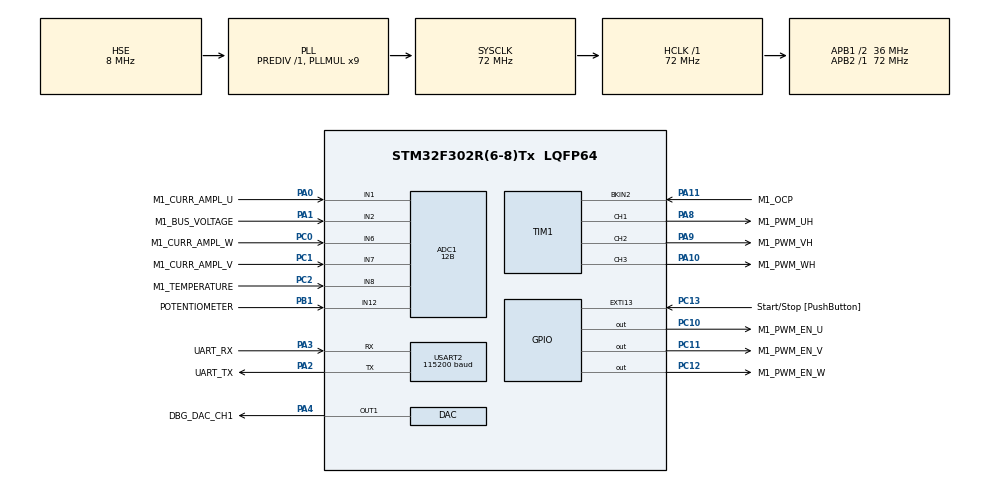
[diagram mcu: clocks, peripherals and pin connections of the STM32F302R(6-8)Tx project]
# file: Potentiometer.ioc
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ADC1.Channel-1\#ChannelRegularConversion=ADC_CHANNEL_2
ADC1.Channel-2\#ChannelRegularConversion=ADC_CHANNEL_8
ADC1.Channel-4\#ChannelRegularConversion=ADC_CHANNEL_12
ADC1.ClockPrescaler=ADC_CLOCK_SYNC_PCLK_DIV1
ADC1.ContinuousConvMode=DISABLE
ADC1.DMAContinuousRequests=DISABLE
ADC1.DataAlign=ADC_DATAALIGN_LEFT
ADC1.DiscontinuousConvMode=DISABLE
ADC1.EOCSelection=ADC_EOC_SINGLE_CONV
ADC1.EnableAnalogWatchDog1=false
ADC1.EnableAnalogWatchDog2=false
ADC1.EnableAnalogWatchDog3=false
ADC1.EnableInjectedConversion=ENABLE
ADC1.EnableRegularConversion=ENABLE
ADC1.ExternalTrigConv=ADC_SOFTWARE_START
ADC1.ExternalTrigConvEdge=ADC_EXTERNALTRIGCONVEDGE_NONE
ADC1.ExternalTrigInjecConv=ADC_EXTERNALTRIGINJECCONV_T1_TRGO
ADC1.ExternalTrigInjecConvEdge=ADC_EXTERNALTRIGINJECCONV_EDGE_RISING
ADC1.InjNumberOfConversion=3
ADC1.InjectedChannel-1\#ChannelInjectedConversion=ADC_CHANNEL_1
ADC1.InjectedChannel-2\#ChannelInjectedConversion=ADC_CHANNEL_7
ADC1.InjectedChannel-3\#ChannelInjectedConversion=ADC_CHANNEL_6
ADC1.InjectedConvMode=None
ADC1.InjectedOffset-1\#ChannelInjectedConversion=0
ADC1.InjectedOffset-2\#ChannelInjectedConversion=0
ADC1.InjectedOffset-3\#ChannelInjectedConversion=0
ADC1.InjectedOffsetNumber-1\#ChannelInjectedConversion=ADC_OFFSET_NONE
ADC1.InjectedOffsetNumber-2\#ChannelInjectedConversion=ADC_OFFSET_NONE
ADC1.InjectedOffsetNumber-3\#ChannelInjectedConversion=ADC_OFFSET_NONE
ADC1.InjectedRank-1\#ChannelInjectedConversion=1
ADC1.InjectedRank-2\#ChannelInjectedConversion=2
ADC1.InjectedRank-3\#ChannelInjectedConversion=3
ADC1.InjectedSamplingTime-1\#ChannelInjectedConversion=ADC_SAMPLETIME_7CYCLES_5
ADC1.InjectedSamplingTime-2\#ChannelInjectedConversion=ADC_SAMPLETIME_7CYCLES_5
ADC1.InjectedSamplingTime-3\#ChannelInjectedConversion=ADC_SAMPLETIME_7CYCLES_5
ADC1.LowPowerAutoWait=DISABLE
ADC1.NbrOfConversion=3
ADC1.NbrOfConversionFlag=1
ADC1.Offset-1\#ChannelRegularConversion=0
ADC1.Offset-2\#ChannelRegularConversion=0
ADC1.Offset-4\#ChannelRegularConversion=0
ADC1.OffsetNumber-1\#ChannelRegularConversion=ADC_OFFSET_NONE
ADC1.OffsetNumber-2\#ChannelRegularConversion=ADC_OFFSET_NONE
ADC1.OffsetNumber-4\#ChannelRegularConversion=ADC_OFFSET_NONE
ADC1.Overrun=ADC_OVR_DATA_PRESERVED
ADC1.QueueInjectedContext=ENABLE
ADC1.Rank-1\#ChannelRegularConversion=1
ADC1.Rank-2\#ChannelRegularConversion=2
ADC1.Rank-4\#ChannelRegularConversion=3
ADC1.Resolution=ADC_RESOLUTION_12B
ADC1.SamplingTime-1\#ChannelRegularConversion=ADC_SAMPLETIME_61CYCLES_5
ADC1.SamplingTime-2\#ChannelRegularConversion=ADC_SAMPLETIME_61CYCLES_5
ADC1.SamplingTime-4\#ChannelRegularConversion=ADC_SAMPLETIME_601CYCLES_5
ADC1.ScanConvMode=ADC_SCAN_ENABLE
ADC1.SubFamily=STM32F302x8
ADC1.master=1
DAC.DAC_OutputBuffer=DAC_OUTPUTBUFFER_DISABLE
DAC.DAC_Trigger=DAC_TRIGGER_SOFTWARE
ExtraMW=MotorControl
ExtraMW.MotorControl.Config=MotorControl
ExtraMW.MotorControl.Mode=MotorControl
ExtraMW.MotorControl.Root=MotorControlDev/
ExtraMW.MotorControl.Template=templates
Mcu.Family=STM32F3
Mcu.Name=STM32F302R(6-8)Tx
Mcu.Package=LQFP64
MotorControl.ADC_1_PERIPH=ADC1
MotorControl.ADC_2_PERIPH=ADC2
MotorControl.ADC_AHBPERIPH=RCC_AHBPeriph_ADC12
MotorControl.ADC_CLOCK_WB_DIV=1
MotorControl.ADC_CLOCK_WB_FREQ=72
MotorControl.ADC_PERIPH=ADC1
MotorControl.ALIGNMENT_ANGLE_DEG=90
MotorControl.ALIGNMENT_DURATION=700
MotorControl.AMPLIFICATION_GAIN=1.53
MotorControl.ANGC={0,0,0,0,0,0,0,0}
MotorControl.BEMF_CONSISTENCY_GAIN=64
MotorControl.BEMF_CONSISTENCY_TOL=64
MotorControl.BKIN1_FILTER=0
MotorControl.BKIN2_FILTER=7
MotorControl.BKIN2_MODE=EXT_MODE
MotorControl.BKIN_MODE=NONE
MotorControl.BOARD=NUCLEO-F302R8
MotorControl.BRKIN2_GPIO_AF=GPIO_AF_12
MotorControl.BRKIN_GPIO_AF=GPIO_AF_2
MotorControl.BUS_VOLTAGE_READING=true
MotorControl.CLOCK_FREQUENCY=CPU_CLK_72_MHZ
MotorControl.CLOCK_SOURCE=EXTERNAL
MotorControl.CONSTANT1_D=95712
MotorControl.CONSTANT1_Q=95712
MotorControl.CONSTANT2_QD=2718
MotorControl.CORD_BEMF_CONSISTENCY_GAIN=64
MotorControl.CORD_BEMF_CONSISTENCY_TOL=64
MotorControl.CORD_F1=1024
MotorControl.CORD_F2=16384
MotorControl.CORD_FIFO_DEPTH_01HZ=64
MotorControl.CORD_FIFO_DEPTH_DPP=64
MotorControl.CORD_GAIN1=-1380
MotorControl.CORD_GAIN2=2895
MotorControl.CORD_MAX_ACCEL_DPPP=30
MotorControl.CORD_MEAS_ERRORS_BEFORE_FAULTS=3
MotorControl.CORD_VARIANCE_THRESHOLD=4
MotorControl.CPU_CLK_72_MHZ=true
MotorControl.CTRBDID=1
MotorControl.CURRENT_READING_TOPOLOGY=THREE_SHUNT
MotorControl.CURR_SAMPLING_TIME=7
MotorControl.DAC_EMULATED=false
MotorControl.DAC_FUNCTIONALITY=true
MotorControl.DAC_TIMER_CH1_GPIO_PIN=LL_GPIO_PIN_4
MotorControl.DAC_TIMER_CH1_GPIO_PORT=GPIOA
MotorControl.DAC_TIMER_CH2_GPIO_PIN=LL_GPIO_PIN_0
MotorControl.DAC_TIMER_CH2_GPIO_PORT=GPIOA
MotorControl.DAC_TIMER_REMAPPING=NO_REMAP
MotorControl.DAC_TIMER_SELECTION=TIM3
MotorControl.DC_CURRENT_RS_MEAS=1.20
MotorControl.DEBUG_DAC_CH1=true
MotorControl.DEBUG_DAC_CH2=false
MotorControl.DEFAULT_CONTROL_MODE=STC_SPEED_MODE
MotorControl.DEFAULT_DAC_CHANNEL_1=MC_PROTOCOL_REG_I_A
MotorControl.DEFAULT_DAC_CHANNEL_2=MC_PROTOCOL_REG_I_B
MotorControl.DEFAULT_DAC_MOTOR=0
MotorControl.DEFAULT_FLUX_COMPONENT=0
MotorControl.DEFAULT_TARGET_SPEED_RPM=3000
MotorControl.DEFAULT_TORQUE_COMPONENT=0
MotorControl.DISSIPATIVE_BRAKE_POLARITY=DOUT_ACTIVE_HIGH
MotorControl.DRIVES_NUMBER_SELECTION=SINGLEDRIVE
MotorControl.EMERGENCY2_STOP_GPIO_PIN=LL_GPIO_PIN_11
MotorControl.EMERGENCY2_STOP_GPIO_PORT=GPIOA
MotorControl.EMERGENCY_STOP_GPIO_PIN=LL_GPIO_PIN_11
MotorControl.EMERGENCY_STOP_GPIO_PORT=GPIOA
MotorControl.ENABLE_SL_ALGO_FROM_PHASE=3
MotorControl.ENCODER_AVAILABLE=false
MotorControl.ENCODER_PPR=400
MotorControl.ENC_AVERAGING_FIFO_DEPTH=16
MotorControl.ENC_A_GPIO_PIN=LL_GPIO_PIN_0
MotorControl.ENC_A_GPIO_PORT=GPIOA
MotorControl.ENC_B_GPIO_PIN=LL_GPIO_PIN_1
MotorControl.ENC_B_GPIO_PORT=GPIOA
MotorControl.ENC_ICx_FILTER=50
MotorControl.ENC_INVERT_SPEED=false
MotorControl.ENC_MEAS_ERRORS_BEFORE_FAULTS=3
MotorControl.ENC_TIMER_REMAPPING=NO_REMAP_TIM2
MotorControl.ENC_TIMER_SELECTION=ENC_TIM2
MotorControl.EXT_CLK_8_MHZ=true
MotorControl.EXT_CLOCK_FREQUENCY=EXT_CLK_8_MHZ
MotorControl.F1=1024
MotorControl.F2=16384
MotorControl.FEEDBACK_NET_FILTERING=false
MotorControl.FEED_FORWARD_CURRENT_REG_ENABLING=false
MotorControl.FINAL_I_ALIGNMENT=19552
MotorControl.FLUX_WEAKENING_ENABLING=false
MotorControl.FW_KIDIV=32768
MotorControl.FW_KI_GAIN=5000
MotorControl.FW_KPDIV=32768
MotorControl.FW_KP_GAIN=3000
MotorControl.FW_VOLTAGE_REF=985
MotorControl.GAIN1=-1380
MotorControl.GAIN2=2895
MotorControl.H1_GPIO_PIN=LL_GPIO_PIN_0
MotorControl.H1_GPIO_PORT=GPIOA
MotorControl.H2_GPIO_PIN=LL_GPIO_PIN_1
MotorControl.H2_GPIO_PORT=GPIOA
MotorControl.H3_GPIO_PIN=LL_GPIO_PIN_2
MotorControl.H3_GPIO_PORT=GPIOA
MotorControl.HALL_AVERAGING_FIFO_DEPTH=6
MotorControl.HALL_ICx_FILTER=94
MotorControl.HALL_MEAS_ERRORS_BEFORE_FAULTS=3
MotorControl.HALL_PHASE_SHIFT=300
MotorControl.HALL_SENSORS_AVAILABLE=false
MotorControl.HALL_SENSORS_PLACEMENT=DEGREES_120
MotorControl.HALL_TIMER_REMAPPING=NO_REMAP_TIM2
MotorControl.HALL_TIMER_SELECTION=HALL_TIM2
MotorControl.HFI_AMPLITUDE=25
MotorControl.HFI_DC_0_COEFF=0.00146
MotorControl.HFI_DC_1_COEFF=0.002921
MotorControl.HFI_DC_2_COEFF=0.00146
MotorControl.HFI_DC_3_COEFF=1.889033
MotorControl.HFI_DC_4_COEFF=-0.894874
MotorControl.HFI_DEBUG_MODE=false
MotorControl.HFI_FREQUENCY=400
MotorControl.HFI_HIFRAMPLSCAN=25
MotorControl.HFI_HP_ID_0_COEFF=0.959381
MotorControl.HFI_HP_ID_1_COEFF=-1.918761
MotorControl.HFI_HP_ID_2_COEFF=0.959381
MotorControl.HFI_HP_ID_3_COEFF=1.917111
MotorControl.HFI_HP_ID_4_COEFF=-0.920412
MotorControl.HFI_IDH_DELAY=32400
MotorControl.HFI_LOCKFREQ=22
MotorControl.HFI_LP_ID_0_COEFF=0.002751
MotorControl.HFI_LP_ID_1_COEFF=0.005502
MotorControl.HFI_LP_ID_2_COEFF=0.002751
MotorControl.HFI_LP_ID_3_COEFF=1.846252
MotorControl.HFI_LP_ID_4_COEFF=-0.857255
MotorControl.HFI_MAXANGLEDIFF=3640
MotorControl.HFI_MINIMUM_SPEED_RPM=402
MotorControl.HFI_NOTCH_IQD_0_COEFF=0.979509
MotorControl.HFI_NOTCH_IQD_1_COEFF=-1.952148
MotorControl.HFI_NOTCH_IQD_2_COEFF=0.979509
MotorControl.HFI_NOTCH_IQD_3_COEFF=1.952148
MotorControl.HFI_NOTCH_IQD_4_COEFF=-0.959018
MotorControl.HFI_NSDETPOINTSSKIP=10
MotorControl.HFI_NSMAXDETPOINTS=20
MotorControl.HFI_NS_MIN_SAT_DIFF=0
MotorControl.HFI_PID_KIDIV=32768
MotorControl.HFI_PID_KI_DEFAULT=400
MotorControl.HFI_PID_KPDIV=16384
MotorControl.HFI_PID_KP_DEFAULT=800
MotorControl.HFI_PLL_KI_DEFAULT=0.00400
MotorControl.HFI_PLL_KP_DEFAULT=0.00060
MotorControl.HFI_RESTARTTIMESEC=0.1
MotorControl.HFI_RESTART_RPM_TH=(((HFI_STO_RPM_TH)+(STO_HFI_RPM_TH))/2)
MotorControl.HFI_REVERT_DIRECTION=true
MotorControl.HFI_SCANROTATIONSNO=3
MotorControl.HFI_SPD_BUFFER_DEPTH_01HZ=64
MotorControl.HFI_STEPANGLE=3640
MotorControl.HFI_STO_RPM_TH=OBS_MINIMUM_SPEED_RPM
MotorControl.HFI_WAITAFTERNS2=4
MotorControl.HFI_WAITBEFORESN=6
MotorControl.HFI_WAITSYNCH=20
MotorControl.HFI_WAITTRACK=20
MotorControl.HIGH_SIDE_BRAKE_STATE=false
MotorControl.HIGH_SIDE_IDLE_STATE=false
MotorControl.HW_COMPLEMENTED_LOW_SIDE=true
MotorControl.HW_DEAD_TIME_NS=800
MotorControl.HW_OV_CURRENT_PROT_BYPASS=false
MotorControl.ID_DEMAG=-12032
MotorControl.INRUSH_CURRLIMIT_AT_POWER_ON=false
MotorControl.INRUSH_CURRLIMIT_CHANGE_AFTER_MS=1000
MotorControl.INRUSH_CURRLIMIT_ENABLING=false
MotorControl.INRUSH_CURRLIMIT_GPIO_PIN=LL_GPIO_PIN_4
MotorControl.INRUSH_CURRLIMIT_GPIO_PORT=GPIOD
MotorControl.INRUSH_CURR_LIMITER_POLARITY=DOUT_ACTIVE_HIGH
MotorControl.INTERNAL_OVERCURRENTPROTECTION=false
MotorControl.INTERNAL_OVERVOLTAGEPROTECTION=false
MotorControl.IQMAX=12032
MotorControl.LCD_JOYSTICK_FUNCTIONALITY=false
MotorControl.LCD_MODE=LCD_FULL
MotorControl.LDLQ_RATIO=1.000
MotorControl.LOW_SIDE_BRAKE_STATE=false
MotorControl.LOW_SIDE_IDLE_STATE=false
MotorControl.LOW_SIDE_SIGNALS_ENABLING=ES_GPIO
MotorControl.LS=0.000018
MotorControl.MAX_APPLICATION_SPEED=18000
MotorControl.MAX_MODULATION_95_PER_CENT=true
MotorControl.MAX_MODULATION_INDEX=MAX_MODULATION_95_PER_CENT
MotorControl.MCU=STM32F302R8
MotorControl.MCU_SUPPLY_VOLTAGE=3.30
MotorControl.MCU_TYPE=STM32F302X8
MotorControl.MC_WORKBENCH_VERSION=5.4.0.19180
MotorControl.MEAS_ERRORS_BEFORE_FAULTS=3
MotorControl.MIN_APPLICATION_SPEED=0
MotorControl.MOTOR_MAX_SPEED_RPM=18000
MotorControl.MOTOR_TYPE=PMSM
MotorControl.MOTOR_VOLTAGE_CONSTANT=0.4
MotorControl.MTPA_ENABLING=false
MotorControl.NB_CONSECUTIVE_TESTS=2
MotorControl.NOMINAL_BUS_VOLTAGE_V=11
MotorControl.NOMINAL_CURRENT=12032
MotorControl.OBS_MEAS_ERRORS_BEFORE_FAULTS=3
MotorControl.OBS_MINIMUM_SPEED_RPM=1000
MotorControl.OCPA_INVERTINGINPUT=COMPX_InvertingInput_VREF
MotorControl.OCPA_INVERTINGINPUT_GPIO_PIN=LL_GPIO_PIN_4
MotorControl.OCPA_INVERTINGINPUT_GPIO_PORT=GPIOA
MotorControl.OCPA_INVERTINGINPUT_MODE=INT_MODE
MotorControl.OCPA_NONINVERTINGINPUT=COMP1_NonInvertingInput_PA1
MotorControl.OCPA_NONINVERTINGINPUT_GPIO_PIN=LL_GPIO_PIN_1
MotorControl.OCPA_NONINVERTINGINPUT_GPIO_PORT=GPIOA
MotorControl.OCPA_OUTPUT=COMP_Output_TIM1BKIN2
MotorControl.OCPA_OUTPUTPOL=COMP_OutputPol_NonInverted
MotorControl.OCPA_OUTPUT_GPIO_AF=GPIO_AF_8
MotorControl.OCPA_OUTPUT_GPIO_PIN=LL_GPIO_PIN_0
MotorControl.OCPA_OUTPUT_GPIO_PORT=GPIOA
MotorControl.OCPA_OUTPUT_MODE=INT_MODE
MotorControl.OCPA_SELECTION=COMP1
MotorControl.OCPB_INVERTINGINPUT=COMPX_InvertingInput_VREF
MotorControl.OCPB_INVERTINGINPUT_GPIO_PIN=LL_GPIO_PIN_4
MotorControl.OCPB_INVERTINGINPUT_GPIO_PORT=GPIOA
MotorControl.OCPB_INVERTINGINPUT_MODE=INT_MODE
MotorControl.OCPB_NONINVERTINGINPUT=COMP2_NonInvertingInput_PA7
MotorControl.OCPB_NONINVERTINGINPUT_GPIO_PIN=LL_GPIO_PIN_7
MotorControl.OCPB_NONINVERTINGINPUT_GPIO_PORT=GPIOA
MotorControl.OCPB_OUTPUT=COMP_Output_TIM1BKIN2
MotorControl.OCPB_OUTPUTPOL=COMP_OutputPol_NonInverted
MotorControl.OCPB_OUTPUT_GPIO_AF=GPIO_AF_8
MotorControl.OCPB_OUTPUT_GPIO_PIN=LL_GPIO_PIN_2
MotorControl.OCPB_OUTPUT_GPIO_PORT=GPIOA
MotorControl.OCPB_OUTPUT_MODE=INT_MODE
MotorControl.OCPB_SELECTION=COMP2
MotorControl.OCPC_INVERTINGINPUT=COMPX_InvertingInput_VREF
MotorControl.OCPC_INVERTINGINPUT_GPIO_PIN=LL_GPIO_PIN_4
MotorControl.OCPC_INVERTINGINPUT_GPIO_PORT=GPIOA
MotorControl.OCPC_INVERTINGINPUT_MODE=INT_MODE
MotorControl.OCPC_NONINVERTINGINPUT=COMP3_NonInvertingInput_PD14
MotorControl.OCPC_NONINVERTINGINPUT_GPIO_PIN=LL_GPIO_PIN_14
MotorControl.OCPC_NONINVERTINGINPUT_GPIO_PORT=GPIOD
MotorControl.OCPC_OUTPUT=COMP_Output_TIM1BKIN2
MotorControl.OCPC_OUTPUTPOL=COMP_OutputPol_NonInverted
MotorControl.OCPC_OUTPUT_GPIO_AF=GPIO_AF_7
MotorControl.OCPC_OUTPUT_GPIO_PIN=LL_GPIO_PIN_8
MotorControl.OCPC_OUTPUT_GPIO_PORT=GPIOC
MotorControl.OCPC_OUTPUT_MODE=INT_MODE
MotorControl.OCPC_SELECTION=COMP3
MotorControl.OCPREF=23830
MotorControl.OCP_COMP_THRESHOLD=0.50
MotorControl.OCP_FILTER=COMP_Mode_HighSpeed
MotorControl.OCP_INVERTINGINPUT=COMPX_InvertingInput_VREF
MotorControl.OCP_INVERTINGINPUT_GPIO_PIN=LL_GPIO_PIN_4
MotorControl.OCP_INVERTINGINPUT_GPIO_PORT=GPIOA
MotorControl.OCP_INVERTINGINPUT_MODE=INT_MODE
MotorControl.OCP_NONINVERTINGINPUT=COMP2_NonInvertingInput_PA7
MotorControl.OCP_NONINVERTINGINPUT_GPIO_PIN=LL_GPIO_PIN_7
MotorControl.OCP_NONINVERTINGINPUT_GPIO_PORT=GPIOA
MotorControl.OCP_OUTPUT=COMP_Output_TIM1BKIN2
MotorControl.OCP_OUTPUTPOL=COMP_OutputPol_NonInverted
MotorControl.OCP_OUTPUT_GPIO_AF=GPIO_AF_8
MotorControl.OCP_OUTPUT_GPIO_PIN=LL_GPIO_PIN_2
MotorControl.OCP_OUTPUT_GPIO_PORT=GPIOA
MotorControl.OCP_OUTPUT_MODE=INT_MODE
MotorControl.OCP_SELECTION=COMP2
MotorControl.OFST={0,0,0,0,0,0,0,0}
MotorControl.ON_OVER_VOLTAGE=TURN_OFF_PWM
MotorControl.OPAMP1_INVERTINGINPUT=OPAMP1_InvertingInput_PGA
MotorControl.OPAMP1_INVERTINGINPUT_GPIO_PIN=LL_GPIO_PIN_3
MotorControl.OPAMP1_INVERTINGINPUT_GPIO_PORT=GPIOA
MotorControl.OPAMP1_INVERTINGINPUT_MODE=INT_MODE
MotorControl.OPAMP1_NONINVERTINGINPUT_PHA=OPAMP1_NonInvertingInput_PA1
MotorControl.OPAMP1_NONINVERTINGINPUT_PHA_GPIO_PIN=LL_GPIO_PIN_1
MotorControl.OPAMP1_NONINVERTINGINPUT_PHA_GPIO_PORT=GPIOA
MotorControl.OPAMP1_NONINVERTINGINPUT_PHB=OPAMP1_NonInvertingInput_PA7
MotorControl.OPAMP1_NONINVERTINGINPUT_PHB_GPIO_PIN=LL_GPIO_PIN_7
MotorControl.OPAMP1_NONINVERTINGINPUT_PHB_GPIO_PORT=GPIOA
MotorControl.OPAMP1_OUT_GPIO_PIN=LL_GPIO_PIN_2
MotorControl.OPAMP1_OUT_GPIO_PORT=GPIOA
MotorControl.OPAMP1_SELECTION=OPAMP1
MotorControl.OPAMP2_INVERTINGINPUT=OPAMP2_InvertingInput_PGA
MotorControl.OPAMP2_INVERTINGINPUT_GPIO_PIN=LL_GPIO_PIN_5
MotorControl.OPAMP2_INVERTINGINPUT_GPIO_PORT=GPIOC
MotorControl.OPAMP2_INVERTINGINPUT_MODE=INT_MODE
MotorControl.OPAMP2_NONINVERTINGINPUT_PHA=OPAMP2_NonInvertingInput_PB0
MotorControl.OPAMP2_NONINVERTINGINPUT_PHA_GPIO_PIN=LL_GPIO_PIN_0
MotorControl.OPAMP2_NONINVERTINGINPUT_PHA_GPIO_PORT=GPIOB
MotorControl.OPAMP2_NONINVERTINGINPUT_PHB=OPAMP2_NonInvertingInput_PA7
MotorControl.OPAMP2_NONINVERTINGINPUT_PHB_GPIO_PIN=LL_GPIO_PIN_7
MotorControl.OPAMP2_NONINVERTINGINPUT_PHB_GPIO_PORT=GPIOA
MotorControl.OPAMP2_NONINVERTINGINPUT_PHC=OPAMP2_NonInvertingInput_PB0
MotorControl.OPAMP2_NONINVERTINGINPUT_PHC_GPIO_PIN=LL_GPIO_PIN_0
MotorControl.OPAMP2_NONINVERTINGINPUT_PHC_GPIO_PORT=GPIOB
MotorControl.OPAMP2_OUT_GPIO_PIN=LL_GPIO_PIN_6
MotorControl.OPAMP2_OUT_GPIO_PORT=GPIOA
MotorControl.OPAMP2_SELECTION=OPAMP2
MotorControl.OPAMP_INVERTINGINPUT=OPAMP1_InvertingInput_PGA
MotorControl.OPAMP_INVERTINGINPUT_GPIO_PIN=LL_GPIO_PIN_3
MotorControl.OPAMP_INVERTINGINPUT_GPIO_PORT=GPIOA
MotorControl.OPAMP_INVERTINGINPUT_MODE=INT_MODE
MotorControl.OPAMP_NONINVERTINGINPUT=OPAMP1_NonInvertingInput_PA7
MotorControl.OPAMP_NONINVERTINGINPUT_GPIO_PIN=LL_GPIO_PIN_7
MotorControl.OPAMP_NONINVERTINGINPUT_GPIO_PORT=GPIOA
MotorControl.OPAMP_OUT_GPIO_PIN=LL_GPIO_PIN_2
MotorControl.OPAMP_OUT_GPIO_PORT=GPIOA
MotorControl.OPAMP_PGACONNECT=OPAMP_PGAConnect_No
MotorControl.OPAMP_PGAGAIN=OPAMP_OPAMP_PGAGain_2
MotorControl.OPAMP_SELECTION=OPAMP1
MotorControl.OPAMP_TYPE_GAIN=INTERNAL
MotorControl.OPEN_LOOP_FOC=false
MotorControl.OPEN_LOOP_K=44
MotorControl.OPEN_LOOP_OFF=4400
MotorControl.OPEN_LOOP_SPEED_RAMP_DURATION_MS=1000
MotorControl.OPEN_LOOP_SPEED_RPM=100
MotorControl.OPEN_LOOP_VF=false
MotorControl.OPEN_LOOP_VOLTAGE_d=6000
MotorControl.OVERCURR_FEEDBACK_POLARITY=EMSTOP2_ACTIVE_LOW
MotorControl.OVERCURR_PROTECTION_HW_DISABLING=DOUT_ACTIVE_HIGH
MotorControl.OVPREF=23830
MotorControl.OVP_FILTER=COMP_Mode_HighSpeed
MotorControl.OVP_INVERTINGINPUT=COMPX_InvertingInput_VREF
MotorControl.OVP_INVERTINGINPUT_GPIO_PIN=LL_GPIO_PIN_4
MotorControl.OVP_INVERTINGINPUT_GPIO_PORT=GPIOA
MotorControl.OVP_INVERTINGINPUT_MODE=INT_MODE
MotorControl.OVP_NONINVERTINGINPUT=COMP2_NonInvertingInput_PA7
MotorControl.OVP_NONINVERTINGINPUT_GPIO_PIN=LL_GPIO_PIN_7
MotorControl.OVP_NONINVERTINGINPUT_GPIO_PORT=GPIOA
MotorControl.OVP_OUTPUT=COMP_Output_TIM1BKIN
MotorControl.OVP_OUTPUTPOL=COMP_OutputPol_NonInverted
MotorControl.OVP_OUTPUT_GPIO_AF=GPIO_AF_8
MotorControl.OVP_OUTPUT_GPIO_PIN=LL_GPIO_PIN_2
MotorControl.OVP_OUTPUT_GPIO_PORT=GPIOA
MotorControl.OVP_OUTPUT_MODE=INT_MODE
MotorControl.OVP_SELECTION=COMP2
MotorControl.OV_CURR_BYPASS_GPIO_PIN=LL_GPIO_PIN_5
MotorControl.OV_CURR_BYPASS_GPIO_PORT=GPIOD
MotorControl.OV_TEMPERATURE_HYSTERESIS_C=10
MotorControl.OV_TEMPERATURE_PROT_ENABLING=true
MotorControl.OV_TEMPERATURE_THRESHOLD_C=110
MotorControl.OV_VOLTAGE_PROT_ENABLING=true
MotorControl.OV_VOLTAGE_THRESHOLD_V=36
MotorControl.PHASE1_DURATION=0
MotorControl.PHASE1_FINAL_CURRENT=0
MotorControl.PHASE1_FINAL_SPEED_RPM=0
MotorControl.PHASE2_DURATION=300
MotorControl.PHASE2_FINAL_CURRENT=10026
MotorControl.PHASE2_FINAL_SPEED_RPM=0
MotorControl.PHASE3_DURATION=100
MotorControl.PHASE3_FINAL_CURRENT=12032
MotorControl.PHASE3_FINAL_SPEED_RPM=133
MotorControl.PHASE4_DURATION=2900
MotorControl.PHASE4_FINAL_CURRENT=12032
MotorControl.PHASE4_FINAL_SPEED_RPM=4000
MotorControl.PHASE5_DURATION=0
MotorControl.PHASE5_FINAL_CURRENT=12032
MotorControl.PHASE5_FINAL_SPEED_RPM=4000
MotorControl.PHASE_CURRENTS_ADC=ADC1_2
MotorControl.PHASE_CURRENTS_CHANNEL=ADC_CHANNEL_9
MotorControl.PHASE_CURRENTS_GPIO_PIN=LL_GPIO_PIN_0
MotorControl.PHASE_CURRENTS_GPIO_PORT=GPIOA
MotorControl.PHASE_UH_GPIO_AF=GPIO_AF_6
MotorControl.PHASE_UH_GPIO_PIN=LL_GPIO_PIN_8
MotorControl.PHASE_UH_GPIO_PORT=GPIOA
MotorControl.PHASE_UH_POLARITY=H_ACTIVE_HIGH
MotorControl.PHASE_UL_GPIO_AF=GPIO_AF_0
MotorControl.PHASE_UL_GPIO_PIN=LL_GPIO_PIN_10
MotorControl.PHASE_UL_GPIO_PORT=GPIOC
MotorControl.PHASE_UL_POLARITY=L_ACTIVE_HIGH
MotorControl.PHASE_U_CURR_ADC=ADC1
MotorControl.PHASE_U_CURR_CHANNEL=ADC_CHANNEL_1
MotorControl.PHASE_U_GPIO_PIN=LL_GPIO_PIN_0
MotorControl.PHASE_U_GPIO_PORT=GPIOA
MotorControl.PHASE_VH_GPIO_AF=GPIO_AF_6
MotorControl.PHASE_VH_GPIO_PIN=LL_GPIO_PIN_9
MotorControl.PHASE_VH_GPIO_PORT=GPIOA
MotorControl.PHASE_VH_POLARITY=H_ACTIVE_HIGH
MotorControl.PHASE_VL_GPIO_AF=GPIO_AF_0
MotorControl.PHASE_VL_GPIO_PIN=LL_GPIO_PIN_11
MotorControl.PHASE_VL_GPIO_PORT=GPIOC
MotorControl.PHASE_VL_POLARITY=L_ACTIVE_HIGH
MotorControl.PHASE_V_CURR_ADC=ADC1
MotorControl.PHASE_V_CURR_CHANNEL=ADC_CHANNEL_7
MotorControl.PHASE_V_GPIO_PIN=LL_GPIO_PIN_1
MotorControl.PHASE_V_GPIO_PORT=GPIOC
MotorControl.PHASE_WH_GPIO_AF=GPIO_AF_6
MotorControl.PHASE_WH_GPIO_PIN=LL_GPIO_PIN_10
MotorControl.PHASE_WH_GPIO_PORT=GPIOA
MotorControl.PHASE_WH_POLARITY=H_ACTIVE_HIGH
MotorControl.PHASE_WL_GPIO_AF=GPIO_AF_0
MotorControl.PHASE_WL_GPIO_PIN=LL_GPIO_PIN_12
MotorControl.PHASE_WL_GPIO_PORT=GPIOC
MotorControl.PHASE_WL_POLARITY=L_ACTIVE_HIGH
MotorControl.PHASE_W_CURR_ADC=ADC1
MotorControl.PHASE_W_CURR_CHANNEL=ADC_CHANNEL_6
MotorControl.PHASE_W_GPIO_PIN=LL_GPIO_PIN_0
MotorControl.PHASE_W_GPIO_PORT=GPIOC
MotorControl.PID_FLUX_KD_DEFAULT=100
MotorControl.PID_FLUX_KI_DEFAULT=214
MotorControl.PID_FLUX_KP_DEFAULT=1051
MotorControl.PID_SPEED_KD_DEFAULT=0
MotorControl.PID_SPEED_KI_DEFAULT=600
MotorControl.PID_SPEED_KP_DEFAULT=1000
MotorControl.PID_TORQUE_KD_DEFAULT=100
MotorControl.PID_TORQUE_KI_DEFAULT=214
MotorControl.PID_TORQUE_KP_DEFAULT=1051
MotorControl.PLL_KI_GAIN=52
MotorControl.PLL_KP_GAIN=2234
MotorControl.POLE_PAIR_NUM=7
MotorControl.PWBDID=2
MotorControl.PWM_FREQUENCY=30000
MotorControl.PWM_TIMER_REMAPPING=PWM_PARTIAL_REMAP
MotorControl.PWM_TIMER_SELECTION=PWM_TIM1
MotorControl.REGCONVADC=ADC1
MotorControl.REGULATION_EXECUTION_RATE=1
MotorControl.RS=0.11
MotorControl.RSHUNT=0.330
MotorControl.R_BRAKE_GPIO_PIN=LL_GPIO_PIN_5
MotorControl.R_BRAKE_GPIO_PORT=GPIOD
MotorControl.R_BRAKE_SWITCH_OFF_THRES_V=29
MotorControl.SEGDIV=0
MotorControl.SERIAL_COMMUNICATION=true
MotorControl.SERIAL_COM_CHANNEL1=MC_PROTOCOL_REG_I_A
MotorControl.SERIAL_COM_CHANNEL2=MC_PROTOCOL_REG_I_A
MotorControl.SERIAL_COM_MODE=COM_BIDIRECTIONAL
MotorControl.SERIAL_COM_MOTOR=0
MotorControl.SHARED_SIGNAL_ENABLE=false
MotorControl.SINGLEDRIVE=true
MotorControl.SPD_DIFFERENTIAL_TERM_ENABLING=false
MotorControl.SPEED_BAND_LOWER_LIMIT=15
MotorControl.SPEED_BAND_UPPER_LIMIT=17
MotorControl.SPEED_FEEDBACK_CHECK=true
MotorControl.SPEED_LOOP_FREQUENCY_HZ=1000
MotorControl.SPEED_SENSOR_SELECTION=STATE_OBSERVER_PLL
MotorControl.SP_KDDIV=16
MotorControl.SP_KIDIV=256
MotorControl.SP_KPDIV=16
MotorControl.STARTING_ANGLE_DEG=90
MotorControl.START_STOP_BTN=true
MotorControl.START_STOP_GPIO_PIN=LL_GPIO_PIN_13
MotorControl.START_STOP_GPIO_PORT=GPIOC
MotorControl.START_STOP_POLARITY=DIN_ACTIVE_LOW
MotorControl.STATE_OBSERVER_PLL=true
MotorControl.STM32F302X8=true
MotorControl.STO_FIFO_DEPTH_01HZ=64
MotorControl.STO_FIFO_DEPTH_DPP=64
MotorControl.STO_HFI_RPM_TH=460
MotorControl.SW_DEADTIME_NS=800
MotorControl.SW_OV_CURRENT_PROT_ENABLING=true
MotorControl.T0_C=25
MotorControl.TEMPERATURE_READING=true
MotorControl.TEMP_ADC_SAMPLING_TIME=61
MotorControl.TEMP_FDBK_ADC=ADC1
MotorControl.TEMP_FDBK_CHANNEL=ADC_CHANNEL_8
MotorControl.TEMP_FDBK_GPIO_PIN=LL_GPIO_PIN_2
MotorControl.TEMP_FDBK_GPIO_PORT=GPIOC
MotorControl.TFDIFFERENTIAL_TERM_ENABLING=false
MotorControl.TF_KDDIV=8192
MotorControl.TF_KIDIV=16384
MotorControl.TF_KPDIV=16384
MotorControl.THREE_SHUNT=true
MotorControl.TNOISE_NS=700
MotorControl.TRANSITION_DURATION=25
MotorControl.TRISE_NS=700
MotorControl.T_MAX=110
MotorControl.UD_VOLTAGE_THRESHOLD_V=5
MotorControl.USART_REMAPPING=NO_REMAP_USART2
MotorControl.USART_RX_GPIO_PIN=LL_GPIO_PIN_3
MotorControl.USART_RX_GPIO_PORT=GPIOA
MotorControl.USART_SELECTION=USE_USART2
MotorControl.USART_SPEED=115200
MotorControl.USART_TX_GPIO_PIN=LL_GPIO_PIN_2
MotorControl.USART_TX_GPIO_PORT=GPIOA
MotorControl.USE_INTERNAL_OPAMP=false
MotorControl.UV_VOLTAGE_PROT_ENABLING=true
MotorControl.V0_V=1.055
MotorControl.VARIANCE_THRESHOLD=0.1
MotorControl.VBUS_ADC=ADC1
MotorControl.VBUS_ADC_SAMPLING_TIME=61
MotorControl.VBUS_CHANNEL=ADC_CHANNEL_2
MotorControl.VBUS_GPIO_PIN=LL_GPIO_PIN_1
MotorControl.VBUS_GPIO_PORT=GPIOA
MotorControl.VBUS_PARTITIONING_FACTOR=0.0522
MotorControl.WB_to_Mx_template_version=19-05-06
MotorControl.WB_to_Mx_version=1.0.1
MotorControl.dV_dT=0.023
NVIC.ADC1_IRQn=true\:2\:0\:true\:true\:false\:3\:true\:true
NVIC.EXTI15_10_IRQn=true\:0\:0\:false\:true\:false\:5\:true\:true
NVIC.PriorityGroup=NVIC_PRIORITYGROUP_3
NVIC.TIM1_BRK_TIM15_IRQn=true\:4\:1\:true\:true\:false\:1\:true\:true
NVIC.TIM1_UP_TIM16_IRQn=true\:0\:0\:false\:true\:false\:2\:true\:true
NVIC.USART2_IRQn=true\:3\:1\:true\:true\:false\:4\:true\:true
PA0.GPIO_Label=M1_CURR_AMPL_U
PA0.Mode=IN1-Single-Ended
PA0.Signal=ADC1_IN1
PA1.GPIO_Label=M1_BUS_VOLTAGE
PA1.Mode=IN2-Single-Ended
PA1.Signal=ADC1_IN2
PA10.GPIO_Label=M1_PWM_WH
PA10.GPIO_PuPd=GPIO_PULLDOWN
PA10.GPIO_Speed=GPIO_SPEED_FREQ_HIGH
PA10.Signal=S_TIM1_CH3
PA11.GPIO_Label=M1_OCP
PA11.GPIO_PuPd=GPIO_PULLUP
PA11.Mode=Activate-Break-Input-2
PA11.Signal=TIM1_BKIN2
PA13.GPIO_Label=TMS
PA13.Mode=Serial_Wire
PA13.Signal=SYS_JTMS-SWDIO
PA14.GPIO_Label=TCK
PA14.Mode=Serial_Wire
PA14.Signal=SYS_JTCK-SWCLK
PA2.GPIO_Label=UART_TX
PA2.GPIO_Mode=GPIO_MODE_AF_PP
PA2.GPIO_PuPd=GPIO_NOPULL
PA2.GPIO_Speed=GPIO_SPEED_FREQ_LOW
PA2.Mode=Asynchronous
PA2.Signal=USART2_TX
PA3.GPIO_Label=UART_RX
PA3.GPIO_Mode=GPIO_MODE_AF_PP
PA3.GPIO_PuPd=GPIO_NOPULL
PA3.GPIO_Speed=GPIO_SPEED_FREQ_LOW
PA3.Mode=Asynchronous
PA3.Signal=USART2_RX
PA4.GPIO_Label=DBG_DAC_CH1
PA4.Signal=COMP_DAC1_group
PA8.GPIO_Label=M1_PWM_UH
PA8.GPIO_PuPd=GPIO_PULLDOWN
PA8.GPIO_Speed=GPIO_SPEED_FREQ_HIGH
PA8.Signal=S_TIM1_CH1
PA9.GPIO_Label=M1_PWM_VH
PA9.GPIO_PuPd=GPIO_PULLDOWN
PA9.GPIO_Speed=GPIO_SPEED_FREQ_HIGH
PA9.Signal=S_TIM1_CH2
PB1.GPIO_Label=POTENTIOMETER
PB1.Mode=IN12-Single-Ended
PB1.Signal=ADC1_IN12
PC0.GPIO_Label=M1_CURR_AMPL_W
PC0.Signal=ADCx_IN6
PC1.GPIO_Label=M1_CURR_AMPL_V
PC1.Signal=ADCx_IN7
PC10.GPIO_Label=M1_PWM_EN_U
PC10.GPIO_PuPd=GPIO_PULLDOWN
PC10.GPIO_Speed=GPIO_SPEED_FREQ_HIGH
PC10.Signal=GPIO_Output
PC11.GPIO_Label=M1_PWM_EN_V
PC11.GPIO_PuPd=GPIO_PULLDOWN
PC11.GPIO_Speed=GPIO_SPEED_FREQ_HIGH
PC11.Signal=GPIO_Output
PC12.GPIO_Label=M1_PWM_EN_W
PC12.GPIO_PuPd=GPIO_PULLDOWN
PC12.GPIO_Speed=GPIO_SPEED_FREQ_HIGH
PC12.Signal=GPIO_Output
PC13.GPIO_Label=Start/Stop [PushButton]
PC13.GPIO_ModeDefaultEXTI=GPIO_MODE_IT_FALLING
PC13.Signal=GPXTI13
PC2.GPIO_Label=M1_TEMPERATURE
PC2.Signal=ADCx_IN8
PF0-OSC_IN.Mode=HSE-External-Oscillator
PF0-OSC_IN.Signal=RCC_OSC_IN
PF1-OSC_OUT.Mode=HSE-External-Oscillator
PF1-OSC_OUT.Signal=RCC_OSC_OUT
ProjectManager.HeapSize=0x200
ProjectManager.StackSize=0x400
ProjectManager.TargetToolchain=TrueSTUDIO
RCC.AHBFreq_Value=72000000
RCC.APB1CLKDivider=RCC_HCLK_DIV2
RCC.APB1Freq_Value=36000000
RCC.APB1TimFreq_Value=72000000
RCC.APB2Freq_Value=72000000
RCC.APB2TimFreq_Value=72000000
RCC.CortexFreq_Value=72000000
RCC.HCLKFreq_Value=72000000
RCC.HSE_VALUE=8000000
RCC.HSI_VALUE=8000000
RCC.LSE_VALUE=32768
RCC.PLLMUL=RCC_PLL_MUL9
RCC.PLLSourceVirtual=RCC_PLLSOURCE_HSE
RCC.SYSCLKFreq_VALUE=72000000
RCC.SYSCLKSourceVirtual=RCC_SYSCLKSOURCE_PLLCLK
RCC.USBFreq_Value=72000000
SH.ADCx_IN6.0=ADC1_IN6,IN6-Single-Ended
SH.ADCx_IN7.0=ADC1_IN7,IN7-Single-Ended
SH.ADCx_IN8.0=ADC1_IN8,IN8-Single-Ended
SH.COMP_DAC1_group.0=DAC_OUT1,DAC_OUT1
SH.S_TIM1_CH1.0=TIM1_CH1,PWM Generation1 CH1
SH.S_TIM1_CH2.0=TIM1_CH2,PWM Generation2 CH2
SH.S_TIM1_CH3.0=TIM1_CH3,PWM Generation3 CH3
TIM1.AutoReloadPreload=TIM_AUTORELOAD_PRELOAD_DISABLE
TIM1.AutomaticOutput=TIM_AUTOMATICOUTPUT_DISABLE
TIM1.Break2Filter=7
TIM1.Break2Polarity=TIM_BREAK2POLARITY_LOW
TIM1.Break2State=TIM_BREAK2_ENABLE
TIM1.BreakFilter=0
TIM1.BreakPolarity=TIM_BREAKPOLARITY_HIGH
TIM1.BreakState=TIM_BREAK_ENABLE
TIM1.Channel=TIM_CHANNEL_4
TIM1.Channel-PWM\ Generation1\ CH1=TIM_CHANNEL_1
TIM1.Channel-PWM\ Generation2\ CH2=TIM_CHANNEL_2
TIM1.Channel-PWM\ Generation3\ CH3=TIM_CHANNEL_3
TIM1.Channel-PWM\ Generation4\ No\ Output=TIM_CHANNEL_4
TIM1.ClearInputSource=TIM_CLEARINPUTSOURCE_NONE
TIM1.ClockDivision=TIM_CLOCKDIVISION_DIV2
TIM1.CounterMode=TIM_COUNTERMODE_CENTERALIGNED1
TIM1.LockLevel=TIM_LOCKLEVEL_1
TIM1.OCFastMode_PWM=TIM_OCFAST_DISABLE
TIM1.OCIdleState_1=TIM_OCIDLESTATE_RESET
TIM1.OCIdleState_2=TIM_OCIDLESTATE_RESET
TIM1.OCIdleState_3=TIM_OCIDLESTATE_RESET
TIM1.OCIdleState_4=TIM_OCIDLESTATE_RESET
TIM1.OCIdleState_5=TIM_OCIDLESTATE_RESET
TIM1.OCIdleState_6=TIM_OCIDLESTATE_RESET
TIM1.OCMode_PWM-PWM\ Generation1\ CH1=TIM_OCMODE_PWM1
TIM1.OCMode_PWM-PWM\ Generation2\ CH2=TIM_OCMODE_PWM1
TIM1.OCMode_PWM-PWM\ Generation3\ CH3=TIM_OCMODE_PWM1
TIM1.OCMode_PWM-PWM\ Generation4\ No\ Output=TIM_OCMODE_PWM2
TIM1.OCPolarity_1=TIM_OCPOLARITY_HIGH
TIM1.OCPolarity_2=TIM_OCPOLARITY_HIGH
TIM1.OCPolarity_3=TIM_OCPOLARITY_HIGH
TIM1.OCPolarity_4=TIM_OCPOLARITY_HIGH
TIM1.OCPolarity_5=TIM_OCPOLARITY_HIGH
TIM1.OCPolarity_6=TIM_OCPOLARITY_HIGH
TIM1.OffStateIDLEMode=TIM_OSSI_ENABLE
TIM1.OffStateRunMode=TIM_OSSR_ENABLE
TIM1.Period=((PWM_PERIOD_CYCLES) / 2)
TIM1.Prescaler=((TIM_CLOCK_DIVIDER) - 1)
TIM1.Pulse-PWM\ Generation1\ CH1=((PWM_PERIOD_CYCLES) / 4)
TIM1.Pulse-PWM\ Generation2\ CH2=((PWM_PERIOD_CYCLES) / 4)
TIM1.Pulse-PWM\ Generation3\ CH3=((PWM_PERIOD_CYCLES) / 4)
TIM1.Pulse-PWM\ Generation4\ No\ Output=(((PWM_PERIOD_CYCLES) / 2) - (HTMIN))
TIM1.Pulse-PWM\ Generation5\ No\ Output=(((PWM_PERIOD_CYCLES) / 2) + 1)
TIM1.Pulse-PWM\ Generation6\ No\ Output=(((PWM_PERIOD_CYCLES) / 2) + 1)
TIM1.RepetitionCounter=(REP_COUNTER)
TIM1.TIM_MasterOutputTrigger=TIM_TRGO_OC4REF
TIM1.TIM_MasterOutputTrigger2=TIM_TRGO2_RESET
TIM1.TIM_MasterSlaveMode=TIM_MASTERSLAVEMODE_DISABLE
TIM1.TIM_SlaveMode=TIM_SLAVEMODE_TRIGGER
USART2.BaudRate=115200
USART2.VirtualMode-Asynchronous=VM_ASYNC
USART2.WordLength=WORDLENGTH_8B
VP_MotorControl_MC_ENABLED.Mode=Enabled
VP_TIM1_VS_ClockSourceITR.Mode=TriggerSource_ITR1
VP_TIM1_VS_ControllerModeTrigger.Mode=Trigger Mode
VP_TIM1_VS_no_output4.Mode=PWM Generation4 No Output
board=MCSDK - Potentiometer

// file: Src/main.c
/**
  ******************************************************************************
  * @file           : main.c
  * @brief          : Main program body
  ******************************************************************************
  * @attention
  *
  * <h2><center>&copy; Copyright (c) 2019 STMicroelectronics.
  * All rights reserved.</center></h2>
  *
  * This software component is licensed by ST under Ultimate Liberty license
  * SLA0044, the "License"; You may not use this file except in compliance with
  * the License. You may obtain a copy of the License at:
  *                             www.st.com/SLA0044
  *
  ******************************************************************************
  */
#include "main.h"
#include "stm32f3xx_hal.h"
#include "motorcontrol.h"

/* USER CODE BEGIN Includes */
#include "potentiometer.h"
#include "regular_conversion_manager.h"

/* USER CODE END Includes */

ADC_HandleTypeDef hadc1;

DAC_HandleTypeDef hdac;

TIM_HandleTypeDef htim1;

UART_HandleTypeDef huart2;

/* USER CODE BEGIN PV */
/* Private variables ---------------------------------------------------------*/
RegConv_t  PotentiometerConv;
uint8_t PotentiometerHandle;

/* USER CODE END PV */

void SystemClock_Config(void);
static void MX_GPIO_Init(void);
static void MX_ADC1_Init(void);
static void MX_DAC_Init(void);
static void MX_TIM1_Init(void);
static void MX_USART2_UART_Init(void);
static void MX_NVIC_Init(void);

void HAL_TIM_MspPostInit(TIM_HandleTypeDef *htim);

int main(void)
{

  /* MCU Configuration----------------------------------------------------------*/

  /* Reset of all peripherals, Initializes the Flash interface and the Systick. */
  HAL_Init();

  /* Configure the system clock */
  SystemClock_Config();

  /* Initialize all configured peripherals */
  MX_GPIO_Init();
  MX_ADC1_Init();
  MX_DAC_Init();
  MX_TIM1_Init();
  MX_USART2_UART_Init();
  MX_MotorControl_Init();

  /* Initialize interrupts */
  MX_NVIC_Init();

  /* Infinite loop */
  /* USER CODE BEGIN WHILE */
  PotentiometerConv.regADC = ADC1 ;
  PotentiometerConv.channel = ADC_CHANNEL_12;
  PotentiometerConv.samplingTime = ADC_SAMPLETIME_61CYCLES_5;
  PotentiometerHandle = RCM_RegisterRegConv (&PotentiometerConv);

  while (1)
  {
    demo_potentiometer(PotentiometerHandle);
  /* USER CODE END WHILE */

  }

}

void SystemClock_Config(void)
{

  RCC_OscInitTypeDef RCC_OscInitStruct;
  RCC_ClkInitTypeDef RCC_ClkInitStruct;
  RCC_PeriphCLKInitTypeDef PeriphClkInit;

    /**Initializes the CPU, AHB and APB busses clocks
    */
  RCC_OscInitStruct.OscillatorType = RCC_OSCILLATORTYPE_HSE;
  RCC_OscInitStruct.HSEState = RCC_HSE_ON;
  RCC_OscInitStruct.HSEPredivValue = RCC_HSE_PREDIV_DIV1;
  RCC_OscInitStruct.HSIState = RCC_HSI_ON;
  RCC_OscInitStruct.PLL.PLLState = RCC_PLL_ON;
  RCC_OscInitStruct.PLL.PLLSource = RCC_PLLSOURCE_HSE;
  RCC_OscInitStruct.PLL.PLLMUL = RCC_PLL_MUL9;
  if (HAL_RCC_OscConfig(&RCC_OscInitStruct) != HAL_OK)
  {
    _Error_Handler(__FILE__, __LINE__);
  }

    /**Initializes the CPU, AHB and APB busses clocks
    */
  RCC_ClkInitStruct.ClockType = RCC_CLOCKTYPE_HCLK|RCC_CLOCKTYPE_SYSCLK
                              |RCC_CLOCKTYPE_PCLK1|RCC_CLOCKTYPE_PCLK2;
  RCC_ClkInitStruct.SYSCLKSource = RCC_SYSCLKSOURCE_PLLCLK;
  RCC_ClkInitStruct.AHBCLKDivider = RCC_SYSCLK_DIV1;
  RCC_ClkInitStruct.APB1CLKDivider = RCC_HCLK_DIV2;
  RCC_ClkInitStruct.APB2CLKDivider = RCC_HCLK_DIV1;

  if (HAL_RCC_ClockConfig(&RCC_ClkInitStruct, FLASH_LATENCY_2) != HAL_OK)
  {
    _Error_Handler(__FILE__, __LINE__);
  }

  PeriphClkInit.PeriphClockSelection = RCC_PERIPHCLK_TIM1;
  PeriphClkInit.Tim1ClockSelection = RCC_TIM1CLK_HCLK;
  if (HAL_RCCEx_PeriphCLKConfig(&PeriphClkInit) != HAL_OK)
  {
    _Error_Handler(__FILE__, __LINE__);
  }

    /**Configure the Systick interrupt time
    */
  HAL_SYSTICK_Config(HAL_RCC_GetHCLKFreq()/1000);

    /**Configure the Systick
    */
  HAL_SYSTICK_CLKSourceConfig(SYSTICK_CLKSOURCE_HCLK);

  /* SysTick_IRQn interrupt configuration */
  HAL_NVIC_SetPriority(SysTick_IRQn, 4, 0);
}

/**
  * @brief NVIC Configuration.
  * @retval None
  */
static void MX_NVIC_Init(void)
{
  /* TIM1_BRK_TIM15_IRQn interrupt configuration */
  HAL_NVIC_SetPriority(TIM1_BRK_TIM15_IRQn, 4, 1);
  HAL_NVIC_EnableIRQ(TIM1_BRK_TIM15_IRQn);
  /* ADC1_IRQn interrupt configuration */
  HAL_NVIC_SetPriority(ADC1_IRQn, 2, 0);
  HAL_NVIC_EnableIRQ(ADC1_IRQn);
  /* USART2_IRQn interrupt configuration */
  HAL_NVIC_SetPriority(USART2_IRQn, 3, 1);
  HAL_NVIC_EnableIRQ(USART2_IRQn);
  /* EXTI15_10_IRQn interrupt configuration */
  HAL_NVIC_SetPriority(EXTI15_10_IRQn, 0, 0);
  HAL_NVIC_EnableIRQ(EXTI15_10_IRQn);
}

/* ADC1 init function */
static void MX_ADC1_Init(void)
{

  ADC_InjectionConfTypeDef sConfigInjected;
  ADC_ChannelConfTypeDef sConfig;

    /**Common config
    */
  hadc1.Instance = ADC1;
  hadc1.Init.ClockPrescaler = ADC_CLOCK_SYNC_PCLK_DIV1;
  hadc1.Init.Resolution = ADC_RESOLUTION_12B;
  hadc1.Init.ScanConvMode = ADC_SCAN_ENABLE;
  hadc1.Init.ContinuousConvMode = DISABLE;
  hadc1.Init.DiscontinuousConvMode = DISABLE;
  hadc1.Init.ExternalTrigConvEdge = ADC_EXTERNALTRIGCONVEDGE_NONE;
  hadc1.Init.ExternalTrigConv = ADC_SOFTWARE_START;
  hadc1.Init.DataAlign = ADC_DATAALIGN_LEFT;
  hadc1.Init.NbrOfConversion = 3;
  hadc1.Init.DMAContinuousRequests = DISABLE;
  hadc1.Init.EOCSelection = ADC_EOC_SINGLE_CONV;
  hadc1.Init.LowPowerAutoWait = DISABLE;
  hadc1.Init.Overrun = ADC_OVR_DATA_PRESERVED;
  if (HAL_ADC_Init(&hadc1) != HAL_OK)
  {
    _Error_Handler(__FILE__, __LINE__);
  }

    /**Configure Injected Channel
    */
  sConfigInjected.InjectedChannel = ADC_CHANNEL_1;
  sConfigInjected.InjectedRank = ADC_INJECTED_RANK_1;
  sConfigInjected.InjectedSingleDiff = ADC_SINGLE_ENDED;
  sConfigInjected.InjectedNbrOfConversion = 3;
  sConfigInjected.InjectedSamplingTime = ADC_SAMPLETIME_7CYCLES_5;
  sConfigInjected.ExternalTrigInjecConvEdge = ADC_EXTERNALTRIGINJECCONV_EDGE_RISING;
  sConfigInjected.ExternalTrigInjecConv = ADC_EXTERNALTRIGINJECCONV_T1_TRGO;
  sConfigInjected.AutoInjectedConv = DISABLE;
  sConfigInjected.InjectedDiscontinuousConvMode = DISABLE;
  sConfigInjected.QueueInjectedContext = ENABLE;
  sConfigInjected.InjectedOffset = 0;
  sConfigInjected.InjectedOffsetNumber = ADC_OFFSET_NONE;
  if (HAL_ADCEx_InjectedConfigChannel(&hadc1, &sConfigInjected) != HAL_OK)
  {
    _Error_Handler(__FILE__, __LINE__);
  }

    /**Configure Injected Channel
    */
  sConfigInjected.InjectedChannel = ADC_CHANNEL_7;
  sConfigInjected.InjectedRank = ADC_INJECTED_RANK_2;
  if (HAL_ADCEx_InjectedConfigChannel(&hadc1, &sConfigInjected) != HAL_OK)
  {
    _Error_Handler(__FILE__, __LINE__);
  }

    /**Configure Injected Channel
    */
  sConfigInjected.InjectedChannel = ADC_CHANNEL_6;
  sConfigInjected.InjectedRank = ADC_INJECTED_RANK_3;
  if (HAL_ADCEx_InjectedConfigChannel(&hadc1, &sConfigInjected) != HAL_OK)
  {
    _Error_Handler(__FILE__, __LINE__);
  }

    /**Configure Regular Channel
    */
  sConfig.Channel = ADC_CHANNEL_2;
  sConfig.Rank = ADC_REGULAR_RANK_1;
  sConfig.SingleDiff = ADC_SINGLE_ENDED;
  sConfig.SamplingTime = ADC_SAMPLETIME_61CYCLES_5;
  sConfig.OffsetNumber = ADC_OFFSET_NONE;
  sConfig.Offset = 0;
  if (HAL_ADC_ConfigChannel(&hadc1, &sConfig) != HAL_OK)
  {
    _Error_Handler(__FILE__, __LINE__);
  }

    /**Configure Regular Channel
    */
  sConfig.Channel = ADC_CHANNEL_8;
  sConfig.Rank = ADC_REGULAR_RANK_2;
  if (HAL_ADC_ConfigChannel(&hadc1, &sConfig) != HAL_OK)
  {
    _Error_Handler(__FILE__, __LINE__);
  }

    /**Configure Regular Channel
    */
  sConfig.Channel = ADC_CHANNEL_12;
  sConfig.Rank = ADC_REGULAR_RANK_3;
  sConfig.SamplingTime = ADC_SAMPLETIME_61CYCLES_5;
  if (HAL_ADC_ConfigChannel(&hadc1, &sConfig) != HAL_OK)
  {
    _Error_Handler(__FILE__, __LINE__);
  }

}

/* DAC init function */
static void MX_DAC_Init(void)
{

  DAC_ChannelConfTypeDef sConfig;

    /**DAC Initialization
    */
  hdac.Instance = DAC;
  if (HAL_DAC_Init(&hdac) != HAL_OK)
  {
    _Error_Handler(__FILE__, __LINE__);
  }

    /**DAC channel OUT1 config
    */
  sConfig.DAC_Trigger = DAC_TRIGGER_SOFTWARE;
  sConfig.DAC_OutputBuffer = DAC_OUTPUTBUFFER_DISABLE;
  if (HAL_DAC_ConfigChannel(&hdac, &sConfig, DAC_CHANNEL_1) != HAL_OK)
  {
    _Error_Handler(__FILE__, __LINE__);
  }

}

/* TIM1 init function */
static void MX_TIM1_Init(void)
{

  TIM_SlaveConfigTypeDef sSlaveConfig;
  TIM_MasterConfigTypeDef sMasterConfig;
  TIM_OC_InitTypeDef sConfigOC;
  TIM_BreakDeadTimeConfigTypeDef sBreakDeadTimeConfig;

  htim1.Instance = TIM1;
  htim1.Init.Prescaler = ((TIM_CLOCK_DIVIDER) - 1);
  htim1.Init.CounterMode = TIM_COUNTERMODE_CENTERALIGNED1;
  htim1.Init.Period = ((PWM_PERIOD_CYCLES) / 2);
  htim1.Init.ClockDivision = TIM_CLOCKDIVISION_DIV2;
  htim1.Init.RepetitionCounter = (REP_COUNTER);
  htim1.Init.AutoReloadPreload = TIM_AUTORELOAD_PRELOAD_DISABLE;
  if (HAL_TIM_Base_Init(&htim1) != HAL_OK)
  {
    _Error_Handler(__FILE__, __LINE__);
  }

  if (HAL_TIM_PWM_Init(&htim1) != HAL_OK)
  {
    _Error_Handler(__FILE__, __LINE__);
  }

  sSlaveConfig.SlaveMode = TIM_SLAVEMODE_TRIGGER;
  sSlaveConfig.InputTrigger = TIM_TS_ITR1;
  if (HAL_TIM_SlaveConfigSynchronization(&htim1, &sSlaveConfig) != HAL_OK)
  {
    _Error_Handler(__FILE__, __LINE__);
  }

  sMasterConfig.MasterOutputTrigger = TIM_TRGO_OC4REF;
  sMasterConfig.MasterOutputTrigger2 = TIM_TRGO2_RESET;
  sMasterConfig.MasterSlaveMode = TIM_MASTERSLAVEMODE_DISABLE;
  if (HAL_TIMEx_MasterConfigSynchronization(&htim1, &sMasterConfig) != HAL_OK)
  {
    _Error_Handler(__FILE__, __LINE__);
  }

  sConfigOC.OCMode = TIM_OCMODE_PWM1;
  sConfigOC.Pulse = ((PWM_PERIOD_CYCLES) / 4);
  sConfigOC.OCPolarity = TIM_OCPOLARITY_HIGH;
  sConfigOC.OCNPolarity = TIM_OCNPOLARITY_HIGH;
  sConfigOC.OCFastMode = TIM_OCFAST_DISABLE;
  sConfigOC.OCIdleState = TIM_OCIDLESTATE_RESET;
  sConfigOC.OCNIdleState = TIM_OCNIDLESTATE_RESET;
  if (HAL_TIM_PWM_ConfigChannel(&htim1, &sConfigOC, TIM_CHANNEL_1) != HAL_OK)
  {
    _Error_Handler(__FILE__, __LINE__);
  }

  if (HAL_TIM_PWM_ConfigChannel(&htim1, &sConfigOC, TIM_CHANNEL_2) != HAL_OK)
  {
    _Error_Handler(__FILE__, __LINE__);
  }

  if (HAL_TIM_PWM_ConfigChannel(&htim1, &sConfigOC, TIM_CHANNEL_3) != HAL_OK)
  {
    _Error_Handler(__FILE__, __LINE__);
  }

  sConfigOC.OCMode = TIM_OCMODE_PWM2;
  sConfigOC.Pulse = (((PWM_PERIOD_CYCLES) / 2) - (HTMIN));
  if (HAL_TIM_PWM_ConfigChannel(&htim1, &sConfigOC, TIM_CHANNEL_4) != HAL_OK)
  {
    _Error_Handler(__FILE__, __LINE__);
  }

  sBreakDeadTimeConfig.OffStateRunMode = TIM_OSSR_ENABLE;
  sBreakDeadTimeConfig.OffStateIDLEMode = TIM_OSSI_ENABLE;
  sBreakDeadTimeConfig.LockLevel = TIM_LOCKLEVEL_1;
  sBreakDeadTimeConfig.DeadTime = 0;
  sBreakDeadTimeConfig.BreakState = TIM_BREAK_ENABLE;
  sBreakDeadTimeConfig.BreakPolarity = TIM_BREAKPOLARITY_HIGH;
  sBreakDeadTimeConfig.BreakFilter = 0;
  sBreakDeadTimeConfig.Break2State = TIM_BREAK2_ENABLE;
  sBreakDeadTimeConfig.Break2Polarity = TIM_BREAK2POLARITY_LOW;
  sBreakDeadTimeConfig.Break2Filter = 7;
  sBreakDeadTimeConfig.AutomaticOutput = TIM_AUTOMATICOUTPUT_DISABLE;
  if (HAL_TIMEx_ConfigBreakDeadTime(&htim1, &sBreakDeadTimeConfig) != HAL_OK)
  {
    _Error_Handler(__FILE__, __LINE__);
  }

  HAL_TIM_MspPostInit(&htim1);

}

/* USART2 init function */
static void MX_USART2_UART_Init(void)
{

  huart2.Instance = USART2;
  huart2.Init.BaudRate = 115200;
  huart2.Init.WordLength = UART_WORDLENGTH_8B;
  huart2.Init.StopBits = UART_STOPBITS_1;
  huart2.Init.Parity = UART_PARITY_NONE;
  huart2.Init.Mode = UART_MODE_TX_RX;
  huart2.Init.HwFlowCtl = UART_HWCONTROL_NONE;
  huart2.Init.OverSampling = UART_OVERSAMPLING_16;
  huart2.Init.OneBitSampling = UART_ONE_BIT_SAMPLE_DISABLE;
  huart2.AdvancedInit.AdvFeatureInit = UART_ADVFEATURE_NO_INIT;
  if (HAL_UART_Init(&huart2) != HAL_OK)
  {
    _Error_Handler(__FILE__, __LINE__);
  }

}

/** Configure pins as
        * Analog
        * Input
        * Output
        * EVENT_OUT
        * EXTI
*/
static void MX_GPIO_Init(void)
{

  GPIO_InitTypeDef GPIO_InitStruct;

  /* GPIO Ports Clock Enable */
  __HAL_RCC_GPIOC_CLK_ENABLE();
  __HAL_RCC_GPIOF_CLK_ENABLE();
  __HAL_RCC_GPIOA_CLK_ENABLE();
  __HAL_RCC_GPIOB_CLK_ENABLE();

  /*Configure GPIO pin Output Level */
  HAL_GPIO_WritePin(GPIOC, M1_PWM_EN_U_Pin|M1_PWM_EN_V_Pin|M1_PWM_EN_W_Pin, GPIO_PIN_RESET);

  /*Configure GPIO pin : Start_Stop_Pin */
  GPIO_InitStruct.Pin = Start_Stop_Pin;
  GPIO_InitStruct.Mode = GPIO_MODE_IT_FALLING;
  GPIO_InitStruct.Pull = GPIO_NOPULL;
  HAL_GPIO_Init(Start_Stop_GPIO_Port, &GPIO_InitStruct);

  /*Configure GPIO pins : M1_PWM_EN_U_Pin M1_PWM_EN_V_Pin M1_PWM_EN_W_Pin */
  GPIO_InitStruct.Pin = M1_PWM_EN_U_Pin|M1_PWM_EN_V_Pin|M1_PWM_EN_W_Pin;
  GPIO_InitStruct.Mode = GPIO_MODE_OUTPUT_PP;
  GPIO_InitStruct.Pull = GPIO_PULLDOWN;
  GPIO_InitStruct.Speed = GPIO_SPEED_FREQ_HIGH;
  HAL_GPIO_Init(GPIOC, &GPIO_InitStruct);

}

void _Error_Handler(char *file, int line)
{
  while(1)
  {
  }
}

/************************ (C) COPYRIGHT STMicroelectronics *****END OF FILE****/
